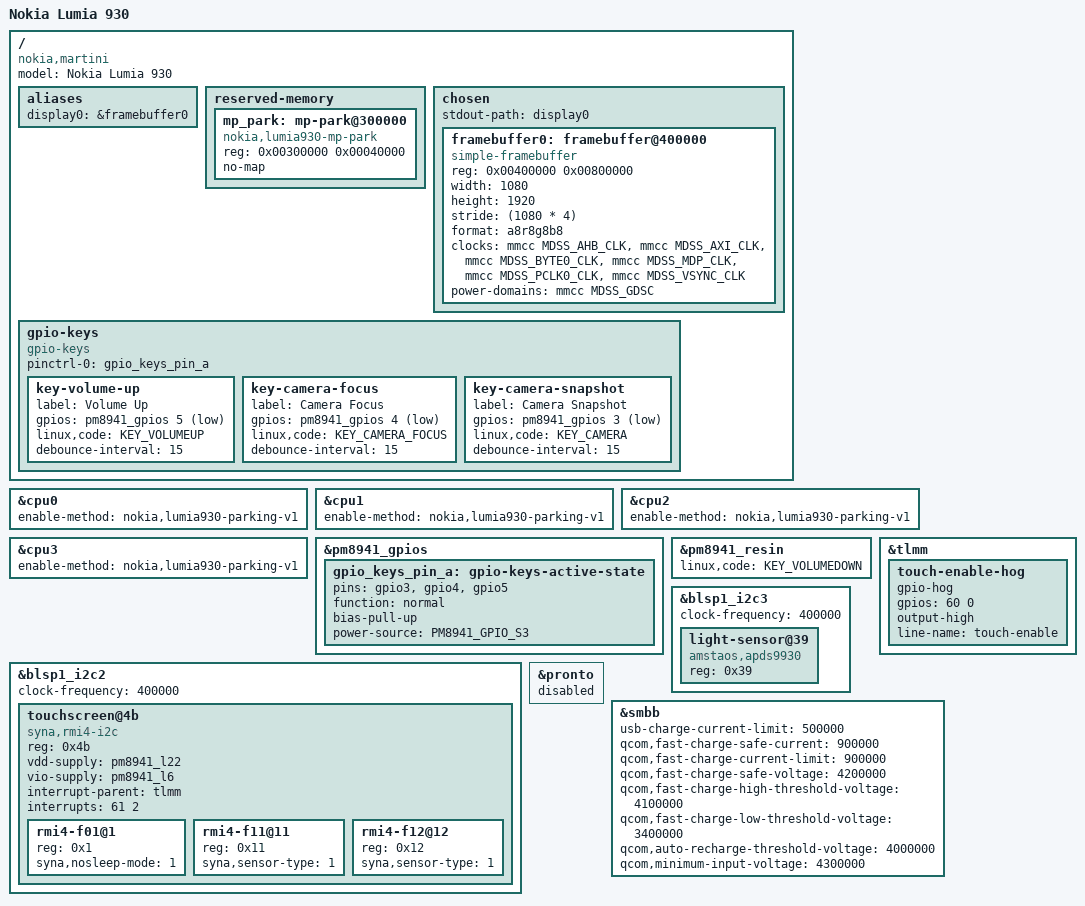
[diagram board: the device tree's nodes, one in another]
// SPDX-License-Identifier: BSD-3-Clause
/*
 * nokia lumia 930 (martini, rm-975). built on the lumia 1520 port of korelis
 * labs (mit, see LICENSE.korelislabs). wiring comes from the stock dsdt and
 * ssdt of this phone, read from the registry.
 */
/dts-v1/;
#include "qcom-msm8974-microsoft-common.dtsi"
#include <dt-bindings/gpio/gpio.h>
#include <dt-bindings/pinctrl/qcom,pmic-gpio.h>

/ {
	model = "Nokia Lumia 930";
	compatible = "nokia,martini", "qcom,msm8974";

	aliases {
		display0 = &framebuffer0;
	};

	reserved-memory {
		mp_park: mp-park@300000 {
			compatible = "nokia,lumia930-mp-park";
			reg = <0x00300000 0x00040000>;
			no-map;
		};
	};

	chosen {
		#address-cells = <1>;
		#size-cells = <1>;
		ranges;
		stdout-path = "display0";

		/* address and size taken from the 1520, not measured on this phone */
		framebuffer0: framebuffer@400000 {
			compatible = "simple-framebuffer";
			reg = <0x00400000 0x00800000>;
			width = <1080>;
			height = <1920>;
			stride = <(1080 * 4)>;
			format = "a8r8g8b8";
			clocks = <&mmcc MDSS_AHB_CLK>,
				 <&mmcc MDSS_AXI_CLK>,
				 <&mmcc MDSS_BYTE0_CLK>,
				 <&mmcc MDSS_MDP_CLK>,
				 <&mmcc MDSS_PCLK0_CLK>,
				 <&mmcc MDSS_VSYNC_CLK>;
			power-domains = <&mmcc MDSS_GDSC>;
		};
	};

	gpio-keys {
		compatible = "gpio-keys";
		pinctrl-names = "default";
		pinctrl-0 = <&gpio_keys_pin_a>;

		key-volume-up {
			label = "Volume Up";
			gpios = <&pm8941_gpios 5 GPIO_ACTIVE_LOW>;
			linux,code = <KEY_VOLUMEUP>;
			debounce-interval = <15>;
		};

		key-camera-focus {
			label = "Camera Focus";
			gpios = <&pm8941_gpios 4 GPIO_ACTIVE_LOW>;
			linux,code = <KEY_CAMERA_FOCUS>;
			debounce-interval = <15>;
		};

		key-camera-snapshot {
			label = "Camera Snapshot";
			gpios = <&pm8941_gpios 3 GPIO_ACTIVE_LOW>;
			linux,code = <KEY_CAMERA>;
			debounce-interval = <15>;
		};
	};
};

&cpu0 {
	enable-method = "nokia,lumia930-parking-v1";
};

&cpu1 {
	enable-method = "nokia,lumia930-parking-v1";
};

&cpu2 {
	enable-method = "nokia,lumia930-parking-v1";
};

&cpu3 {
	enable-method = "nokia,lumia930-parking-v1";
};

&pm8941_gpios {
	gpio_keys_pin_a: gpio-keys-active-state {
		pins = "gpio3", "gpio4", "gpio5";
		function = "normal";
		bias-pull-up;
		power-source = <PM8941_GPIO_S3>;
	};
};

&pm8941_resin {
	status = "okay";
	linux,code = <KEY_VOLUMEDOWN>;
};

/* bus, address and gpios are from the dsdt (NOKIA_TOUCH). family and supplies are not */
&blsp1_i2c2 {
	status = "okay";
	clock-frequency = <400000>;

	touchscreen@4b {
		compatible = "syna,rmi4-i2c";
		reg = <0x4b>;
		vdd-supply = <&pm8941_l22>;
		vio-supply = <&pm8941_l6>;
		interrupt-parent = <&tlmm>;
		interrupts = <61 2>;

		#address-cells = <1>;
		#size-cells = <0>;

		rmi4-f01@1 {
			reg = <0x1>;
			syna,nosleep-mode = <1>;
		};

		rmi4-f11@11 {
			reg = <0x11>;
			syna,sensor-type = <1>;
		};

		rmi4-f12@12 {
			reg = <0x12>;
			syna,sensor-type = <1>;
		};
	};
};

&tlmm {
	touch-enable-hog {
		gpio-hog;
		gpios = <60 0>;
		output-high;
		line-name = "touch-enable";
	};
};

/* address is from the ssdt (QPDS_APS), its interrupt is tlmm gpio 74, edge, active low */
&blsp1_i2c3 {
	status = "okay";
	clock-frequency = <400000>;

	light-sensor@39 {
		compatible = "amstaos,apds9930";
		reg = <0x39>;
	};
};

/* wifi never signals ready on the 1520 and a failed start can reset the phone */
&pronto {
	status = "disabled";
};

/*
 * bv-5qw, 2500 mah. limits follow the default table of the stock battery.json
 * (4.1 v, 900 ma), since linux cannot do the bif authentication that unlocks
 * 4.35 v. untested on this phone.
 */
&smbb {
	usb-charge-current-limit = <500000>;
	qcom,fast-charge-safe-current = <900000>;
	qcom,fast-charge-current-limit = <900000>;
	qcom,fast-charge-safe-voltage = <4200000>;
	qcom,fast-charge-high-threshold-voltage = <4100000>;
	qcom,fast-charge-low-threshold-voltage = <3400000>;
	qcom,auto-recharge-threshold-voltage = <4000000>;
	qcom,minimum-input-voltage = <4300000>;

	status = "okay";
};
